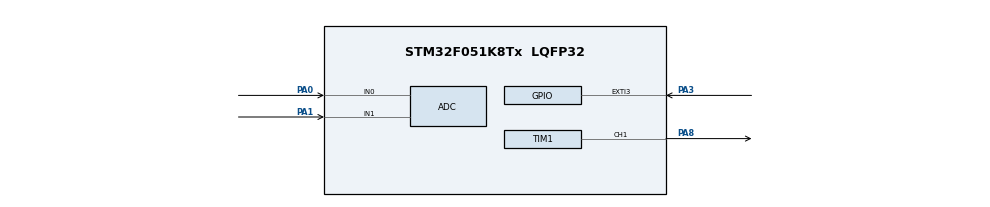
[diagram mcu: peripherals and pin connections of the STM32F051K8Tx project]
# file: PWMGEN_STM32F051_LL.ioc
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ADC.ContinuousConvMode=ENABLE
ADC.DMAContinuousRequests=ENABLE
ADC.Overrun=ADC_OVR_DATA_OVERWRITTEN
Dma.ADC.0.Direction=DMA_PERIPH_TO_MEMORY
Dma.ADC.0.Instance=DMA1_Channel1
Dma.ADC.0.MemDataAlignment=DMA_MDATAALIGN_WORD
Dma.ADC.0.MemInc=DMA_MINC_ENABLE
Dma.ADC.0.Mode=DMA_CIRCULAR
Dma.ADC.0.PeriphDataAlignment=DMA_PDATAALIGN_WORD
Dma.ADC.0.PeriphInc=DMA_PINC_DISABLE
Dma.ADC.0.Priority=DMA_PRIORITY_LOW
Dma.Request0=ADC
Mcu.Family=STM32F0
Mcu.Name=STM32F051K8Tx
Mcu.Package=LQFP32
NVIC.DMA1_Channel1_IRQn=true\:0\:0\:false\:false\:true\:false\:true
NVIC.EXTI2_3_IRQn=true\:0\:0\:false\:false\:true\:true\:true
NVIC.TIM17_IRQn=true\:0\:0\:false\:false\:true\:true\:true
PA0.Mode=IN0
PA0.Signal=ADC_IN0
PA1.Mode=IN1
PA1.Signal=ADC_IN1
PA13.Mode=Serial_Wire
PA13.Signal=SYS_SWDIO
PA14.Mode=Serial_Wire
PA14.Signal=SYS_SWCLK
PA3.GPIO_ModeDefaultEXTI=GPIO_MODE_IT_FALLING
PA3.GPIO_PuPd=GPIO_PULLUP
PA3.Signal=GPXTI3
PA8.Signal=S_TIM1_CH1
ProjectManager.HeapSize=0x200
ProjectManager.StackSize=0x400
ProjectManager.TargetToolchain=TrueSTUDIO
RCC.AHBFreq_Value=48000000
RCC.APB1Freq_Value=48000000
RCC.APB1TimFreq_Value=48000000
RCC.HCLKFreq_Value=48000000
RCC.PLLMUL=RCC_PLL_MUL12
RCC.SYSCLKFreq_VALUE=48000000
RCC.SYSCLKSource=RCC_SYSCLKSOURCE_PLLCLK
SH.S_TIM1_CH1.0=TIM1_CH1,PWM Generation1 CH1
TIM1.AutoReloadPreload=TIM_AUTORELOAD_PRELOAD_ENABLE
TIM1.Channel-PWM\ Generation1\ CH1=TIM_CHANNEL_1
TIM1.OCFastMode_PWM-PWM\ Generation1\ CH1=TIM_OCFAST_ENABLE
TIM1.Period=18
TIM1.Prescaler=1
TIM1.TIM_MasterOutputTrigger=TIM_TRGO_UPDATE
TIM16.AutoReloadPreload=TIM_AUTORELOAD_PRELOAD_ENABLE
TIM16.Period=1024
TIM16.Prescaler=1024
TIM17.AutoReloadPreload=TIM_AUTORELOAD_PRELOAD_ENABLE
TIM17.Period=4
TIM17.Prescaler=1
VP_TIM16_VS_ClockSourceINT.Mode=Enable_Timer
VP_TIM17_VS_ClockSourceINT.Mode=Enable_Timer
VP_TIM1_VS_ClockSourceINT.Mode=Internal
board=custom

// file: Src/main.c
/* USER CODE BEGIN Header */
/**
  ******************************************************************************
  * @file           : main.c
  * @brief          : Main program body
  ******************************************************************************
  * @attention
  *
  * <h2><center>&copy; Copyright (c) 2019 STMicroelectronics.
  * All rights reserved.</center></h2>
  *
  * This software component is licensed by ST under BSD 3-Clause license,
  * the "License"; You may not use this file except in compliance with the
  * License. You may obtain a copy of the License at:
  *                        opensource.org/licenses/BSD-3-Clause
  *
  ******************************************************************************
  */
/* USER CODE END Header */

#include "main.h"
#include "adc.h"
#include "dma.h"
#include "tim.h"
#include "gpio.h"

/* USER CODE BEGIN PV */
uint32_t input[SAMPLE_RESOLUTION] = {0};

uint32_t lastdebouncetime = 0;
uint32_t maxdebouncedelay = 500;

/* USER CODE END PV */

void SystemClock_Config(void);

int main(void)
{

  /* MCU Configuration--------------------------------------------------------*/

  /* Reset of all peripherals, Initializes the Flash interface and the Systick. */
  HAL_Init();

  /* Configure the system clock */
  SystemClock_Config();

  /* Initialize all configured peripherals */
  MX_GPIO_Init();
  MX_DMA_Init();
  MX_TIM1_Init();
  MX_ADC_Init();
  MX_TIM17_Init();
  MX_TIM16_Init();
  /* USER CODE BEGIN 2 */

/*  LL_ADC_StartCalibration(ADC1);
  while(LL_ADC_IsCalibrationOnGoing(ADC1))
  {
	  // wait for calibration
  }

  DMA1_Channel1->CCR = DMA_CCR_EN;
  DMA1_Channel1->CNDTR = SAMPLE_RESOLUTION;
  DMA1_Channel1->CMAR = (uint32_t)input;
  DMA1_Channel1->CPAR = ADC1->DR;

  ADC1->CFGR1 |= ADC_CFGR1_DMAEN;
  ADC1->CR = ADC_CR_ADEN;
  ADC1->CR = ADC_CR_ADSTART;
*/

  HAL_ADCEx_Calibration_Start(&hadc);
  HAL_ADC_Start_DMA(&hadc, input, SAMPLE_RESOLUTION);

  LL_TIM_CC_EnableChannel(TIM1, LL_TIM_CHANNEL_CH1);
  LL_TIM_EnableCounter(TIM1);
  LL_TIM_EnableAutomaticOutput(TIM1);

  LL_TIM_EnableCounter(TIM16);
  LL_TIM_EnableIT_UPDATE(TIM16);

  LL_TIM_EnableCounter(TIM17);
  LL_TIM_EnableIT_UPDATE(TIM17);

  /* USER CODE END 2 */

  /* Infinite loop */
  /* USER CODE BEGIN WHILE */
  while (1)
  {
	  TIM1->CCR1 = 8;
	  LL_mDelay(10);
    /* USER CODE END WHILE */

  }
}

void SystemClock_Config(void)
{
  LL_FLASH_SetLatency(LL_FLASH_LATENCY_1);

  if(LL_FLASH_GetLatency() != LL_FLASH_LATENCY_1)
  {
  Error_Handler();
  }
  LL_RCC_HSI_Enable();

   /* Wait till HSI is ready */
  while(LL_RCC_HSI_IsReady() != 1)
  {

  }
  LL_RCC_HSI_SetCalibTrimming(16);
  LL_RCC_HSI14_Enable();

   /* Wait till HSI14 is ready */
  while(LL_RCC_HSI14_IsReady() != 1)
  {

  }
  LL_RCC_HSI14_SetCalibTrimming(16);
  LL_RCC_PLL_ConfigDomain_SYS(LL_RCC_PLLSOURCE_HSI_DIV_2, LL_RCC_PLL_MUL_12);
  LL_RCC_PLL_Enable();

   /* Wait till PLL is ready */
  while(LL_RCC_PLL_IsReady() != 1)
  {

  }
  LL_RCC_SetAHBPrescaler(LL_RCC_SYSCLK_DIV_1);
  LL_RCC_SetAPB1Prescaler(LL_RCC_APB1_DIV_1);
  LL_RCC_SetSysClkSource(LL_RCC_SYS_CLKSOURCE_PLL);

   /* Wait till System clock is ready */
  while(LL_RCC_GetSysClkSource() != LL_RCC_SYS_CLKSOURCE_STATUS_PLL)
  {

  }
  LL_Init1msTick(48000000);
  LL_SYSTICK_SetClkSource(LL_SYSTICK_CLKSOURCE_HCLK);
  LL_SetSystemCoreClock(48000000);
  LL_RCC_HSI14_EnableADCControl();
}

void Error_Handler(void)
{
}

/************************ (C) COPYRIGHT STMicroelectronics *****END OF FILE****/
